# f28p65x_lin_regs register map
Vendor: Texas Instruments
Peripheral module from a debugger description file (folder C2000).
Address unit: 16 bits
Registers are 32-bit, read-write, no defined reset value unless marked. A register's access mark holds for its fields unless they carry their own. Offsets are as the file gives them; lines under a group give offsets from that group; [hi:lo] are bit positions; {n}, {i} and the like mark numbered series; 'fields as' and 'values as' point back to an identical list; <NAME> marks a mode.

## LIN_REGS — LIN Registers
0x00 SCIGCR0 — Global Control Register 0
  [0] RESET — LIN Module reset bit
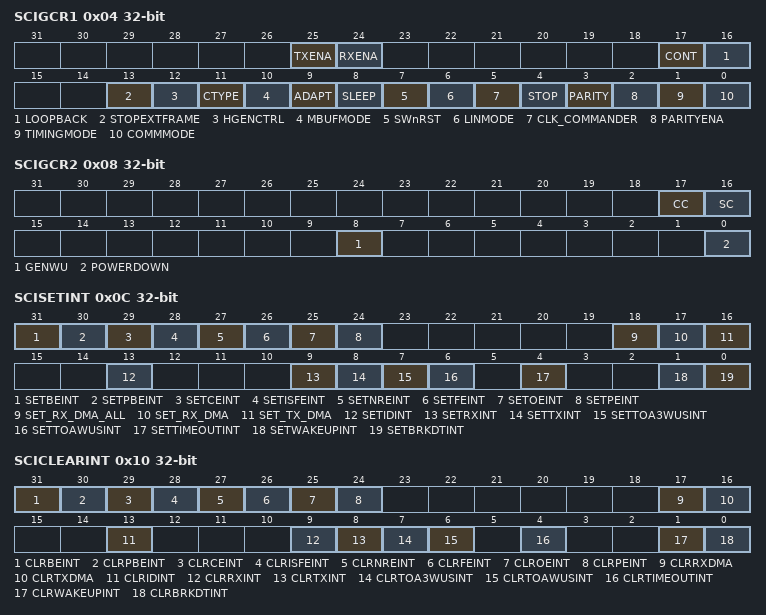
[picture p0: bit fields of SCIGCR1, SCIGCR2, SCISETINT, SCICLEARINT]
0x04 SCIGCR1 — Global Control Register 1
  [25] TXENA — Transmit enable
  [24] RXENA — Receive enable
  [17] CONT — Continue on suspend
  [16] LOOPBACK — Digital loopback mode
  [13] STOPEXTFRAME — Stop extended frame communication (LIN mode)
  [12] HGENCTRL — Mask filtering comparison control (LIN mode)
  [11] CTYPE — Checksum type (LIN mode)
  [10] MBUFMODE — Multi-buffer mode
  [9] ADAPT — Automatic baudrate adjustment control(LIN mode)
  [8] SLEEP — SCI sleep (SCI compatibility mode)
  [7] SWnRST — Software reset
  [6] LINMODE — LIN Mode enable/disable
  [5] CLK_COMMANDER — LIN Commander/Responder selection and SCI clock enable
  [4] STOP — SCI number of stop bits
  [3] PARITY — SCI parity odd/even selection
  [2] PARITYENA — Parity enable
  [1] TIMINGMODE — SCI timing mode bit. Should be set to 1 for SCI mode.
  [0] COMMMODE — SCI/LIN communications mode bit
0x08 SCIGCR2 — Global Control Register 2
  [17] CC — Compare Checksum (LIN mode)
  [16] SC — Send Checksum (LIN mode)
  [8] GENWU — Generate Wakeup
  [0] POWERDOWN — Low-power mode PowerDown bit
0x0C SCISETINT — Interrupt Enable Register
  [31] SETBEINT — Set Bit Error Interrupt (LIN only)
  [30] SETPBEINT — Set Physical Bus Error Interrupt (LIN only)
  [29] SETCEINT — Set Checksum-error Interrupt (LIN only)
  [28] SETISFEINT — Set Inconsistent-Sync-Field-Error Interrupt (LIN only)
  [27] SETNREINT — Set No-Response-Error Interrupt (LIN only)
  [26] SETFEINT — Set Framing-Error Interrupt
  [25] SETOEINT — Set Overrun-Error Interrupt
  [24] SETPEINT — Set Parity Interrupt
  [18] SET_RX_DMA_ALL — Set receiver DMA for Address and Data frames
  [17] SET_RX_DMA — Set receiver DMA
  [16] SET_TX_DMA — Set transmit DMA
  [13] SETIDINT — Set Identifier Interrupt (LIN only)
  [9] SETRXINT — Se Receiver Interrupt
  [8] SETTXINT — Set Transmitter Interrupt
  [7] SETTOA3WUSINT — Set Timeout After 3 Wakeup Signals Interrupt (LIN only)
  [6] SETTOAWUSINT — Set Timeout After Wakeup Signal Interrupt (LIN only)
  [4] SETTIMEOUTINT — Set Timeout Interrupt (LIN only)
  [1] SETWAKEUPINT — Set Wake-up Interrupt
  [0] SETBRKDTINT — Set Break-detect Interrupt (SCI compatible mode)
0x10 SCICLEARINT — Interrupt Disable Register
  [31] CLRBEINT — Clear Bit Error Interrupt (LIN only)
  [30] CLRPBEINT — Clear Physical Bus Error Interrupt (LIN only)
  [29] CLRCEINT — Clear Checksum-error Interrupt (LIN only)
  [28] CLRISFEINT — Clear Inconsistent-Sync-Field-Error Interrupt (LIN only)
  [27] CLRNREINT — Clear No-Response-Error Interrupt (LIN only)
  [26] CLRFEINT — Clear Framing-Error Interrupt
  [25] CLROEINT — Clear Overrun-Error Interrupt
  [24] CLRPEINT — Clear Parity Interrupt
  [17] CLRRXDMA — Clear receiver DMA
  [16] CLRTXDMA — Clear transmit DMA
  [13] CLRIDINT — Clear Identifier Interrupt (LIN only)
  [9] CLRRXINT — Clear Receiver Interrupt
  [8] CLRTXINT — Clear Transmitter Interrupt
  [7] CLRTOA3WUSINT — Clear Timeout After 3 Wakeup Signals Interrupt (LIN only)
  [6] CLRTOAWUSINT — Clear Timeout After Wakeup Signal Interrupt (LIN only)
  [4] CLRTIMEOUTINT — Clear Timeout Interrupt (LIN only)
  [1] CLRWAKEUPINT — Clear Wake-up Interrupt
  [0] CLRBRKDTINT — Clear Break-detect Interrupt (SCI compatible mode
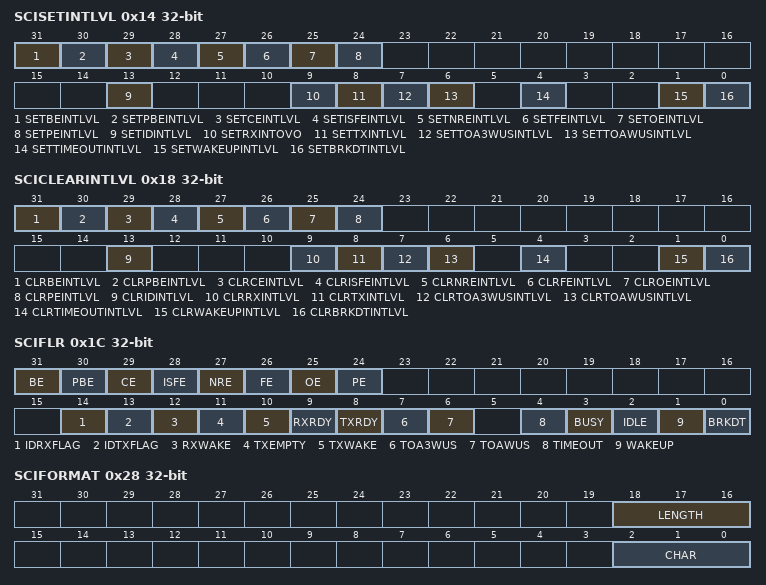
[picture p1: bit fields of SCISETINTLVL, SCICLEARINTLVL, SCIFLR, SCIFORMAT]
0x14 SCISETINTLVL — Set Interrupt Level Register
  [31] SETBEINTLVL — Set Bit Error Interrupt Level (LIN only)
  [30] SETPBEINTLVL — Set Physical Bus Error Interrupt Level (LIN only)
  [29] SETCEINTLVL — Set Checksum-error Interrupt Level (LIN only)
  [28] SETISFEINTLVL — Set Inconsistent-Sync-Field-Error Interrupt Level
  [27] SETNREINTLVL — Set No-Response-Error Interrupt Level (LIN only)
  [26] SETFEINTLVL — Set Framing-Error Interrupt Level
  [25] SETOEINTLVL — Set Overrun-Error Interrupt Level
  [24] SETPEINTLVL — Set Parity Interrupt Level
  [13] SETIDINTLVL — Set Identifier Interrupt Level (LIN only)
  [9] SETRXINTOVO — Receiver Interrupt Enable Level
  [8] SETTXINTLVL — Set Transmitter Interrupt Level
  [7] SETTOA3WUSINTLVL — Set Timeout After 3 Wakeup Signals Interrupt Level
  [6] SETTOAWUSINTLVL — Set Timeout After Wakeup Signal Interrupt Level (LIN only)
  [4] SETTIMEOUTINTLVL — Set Timeout Interrupt Level (LIN only)
  [1] SETWAKEUPINTLVL — Set Wake-up Interrupt Level
  [0] SETBRKDTINTLVL — Set Break-detect Interrupt Level (SCI compatible mode)
0x18 SCICLEARINTLVL — Clear Interrupt Level Register
  [31] CLRBEINTLVL — Clear Bit Error Interrupt Level (LIN only)
  [30] CLRPBEINTLVL — Clear Physical Bus Error Interrupt Level (LIN only)
  [29] CLRCEINTLVL — Clear Checksum-error Interrupt Level (LIN only)
  [28] CLRISFEINTLVL — Clear Inconsistent-Sync-Field-Error
  [27] CLRNREINTLVL — Clear No-Response-Error Interrupt Level (LIN only)
  [26] CLRFEINTLVL — Clear Framing-Error Interrupt Level
  [25] CLROEINTLVL — Clear Overrun-Error Interrupt Level
  [24] CLRPEINTLVL — Clear Parity Interrupt Level
  [13] CLRIDINTLVL — Clear Identifier Interrupt Level (LIN only)
  [9] CLRRXINTLVL — Clear Receiver interrupt Level.
  [8] CLRTXINTLVL — Clear Transmitter Interrupt Level
  [7] CLRTOA3WUSINTLVL — Clear Timeout After 3 Wakeup Signals
  [6] CLRTOAWUSINTLVL — Clear Timeout After Wakeup Signal Interrupt Level (LIN only)
  [4] CLRTIMEOUTINTLVL — Clear Timeout Interrupt Level (LIN only)
  [1] CLRWAKEUPINTLVL — Clear Wake-up Interrupt Level
  [0] CLRBRKDTINTLVL — Clear Break-detect Interrupt Level (SCI compatible mode)
0x1C SCIFLR access per field — Flag Register
  [31] BE rw — Bit Error Flag (LIN only)
  [30] PBE rw — Physical Bus Error Flag (LIN only)
  [29] CE rw — Checksum Error Flag (LIN only)
  [28] ISFE rw — Inconsistent Sync Field Error Flag (LIN only)
  [27] NRE rw — No-Response Error Flag (LIN only)
  [26] FE rw — Framing Error Flag
  [25] OE rw — Overrun Error Flag
  [24] PE rw — Parity Error Flag
  [14] IDRXFLAG rw — Identifier on Receive Flag
  [13] IDTXFLAG rw — Identifier On Transmit Flag (LIN only)
  [12] RXWAKE ro — Receiver Wakeup Detect Flag
  [11] TXEMPTY ro — Transmitter Empty Flag
  [10] TXWAKE rw — SCI Transmitter Wakeup Method Select
  [9] RXRDY rw — Receiver Buffer Ready Flag
  [8] TXRDY ro — Transmitter Buffer Ready Flag
  [7] TOA3WUS rw — Timeout After 3 Wakeup Signals Flag (LIN only)
  [6] TOAWUS rw — Timeout After Wakeup Signal Flag (LIN only)
  [4] TIMEOUT rw — LIN Bus IDLE timeout Flag (LIN only)
  [3] BUSY ro — Busy Flag
  [2] IDLE ro — SCI receiver in idle state (SCI compatible mode)
  [1] WAKEUP rw — Wake-up Flag
  [0] BRKDT rw — Break-detect Flag (SCI compatible mode)
0x20 SCIINTVECT0 ro — Interrupt Vector Offset Register 0
  [4:0] INTVECT0 — LIN Module reset bit
0x24 SCIINTVECT1 ro — Interrupt Vector Offset Register 1
  [4:0] INTVECT1 — LIN Module reset bit
0x28 SCIFORMAT — Length Control Register
  [18:16] LENGTH — Frame Length Control Bits
  [2:0] CHAR — Character Length Control Bits
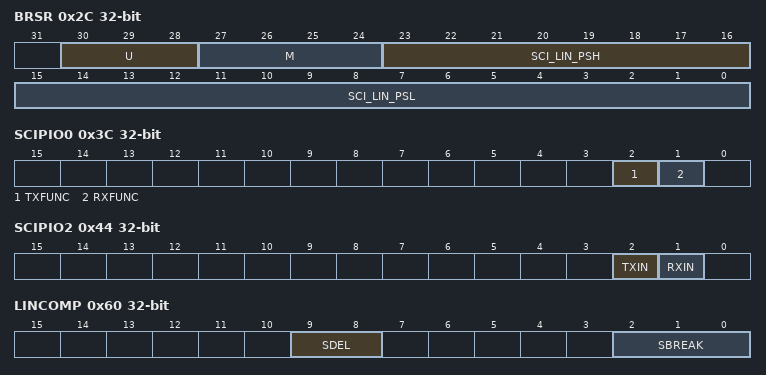
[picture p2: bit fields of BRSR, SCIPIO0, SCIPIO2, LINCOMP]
0x2C BRSR — Baud Rate Selection Register
  [30:28] U — U Superfractional divider Selection
  [27:24] M — M 4-bit Fractional Divider selection
  [23:16] SCI_LIN_PSH — 24-Bit Integer Prescaler Select (High Bits)
  [15:0] SCI_LIN_PSL — 24-Bit Integer Prescaler Select (Low Bits)
0x30 SCIED ro — Emulation buffer Register
  [7:0] ED — Receiver Emulation Data.
0x34 SCIRD ro — Receiver data buffer Register
  [7:0] RD — Received Data.
0x38 SCITD — Transmit data buffer Register
  [7:0] TD — Transmit data
0x3C SCIPIO0 — Pin control Register 0
  [2] TXFUNC — LINTX pin function
  [1] RXFUNC — LINRX pin function
0x44 SCIPIO2 ro — Pin control Register 2
  [2] TXIN — SCITX pin value
  [1] RXIN — SCIRX pin value
0x60 LINCOMP — Compare register
  [9:8] SDEL — Sync Delimiter Compare
  [2:0] SBREAK — Sync Break Extend
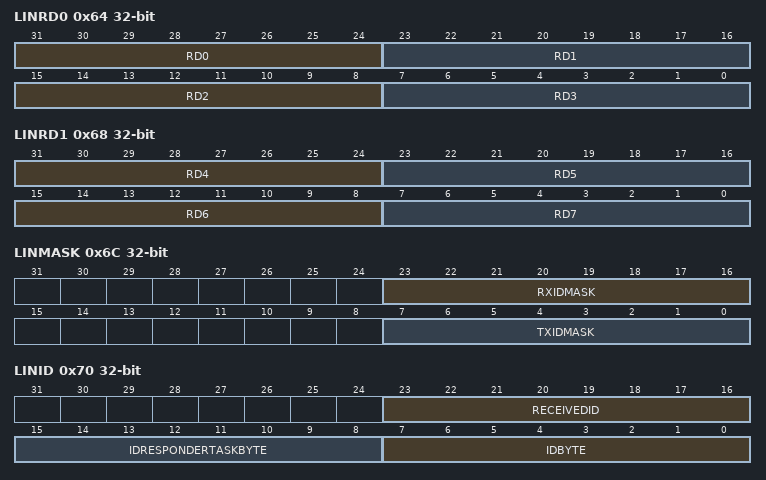
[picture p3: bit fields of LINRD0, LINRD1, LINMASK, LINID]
0x64 LINRD0 ro — Receive data register 0
  [31-8n:24-8n] RD{n} (n=0..3) — Receive Buffer {n}
0x68 LINRD1 ro — Receive data register 1
  [63-8n:56-8n] RD{n} (n=4..7) — Receive Buffer {n-4}
0x6C LINMASK — Acceptance mask register
  [23:16] RXIDMASK — RX ID Mask bits (LIN only)
  [7:0] TXIDMASK — TX ID Mask bits (LIN only)
0x70 LINID access per field
  [23:16] RECEIVEDID ro — Current Message ID (LIN only)
  [15:8] IDRESPONDERTASKBYTE rw — ID Responder Task byte (LIN only)
  [7:0] IDBYTE rw — LIN message ID (LIN only)
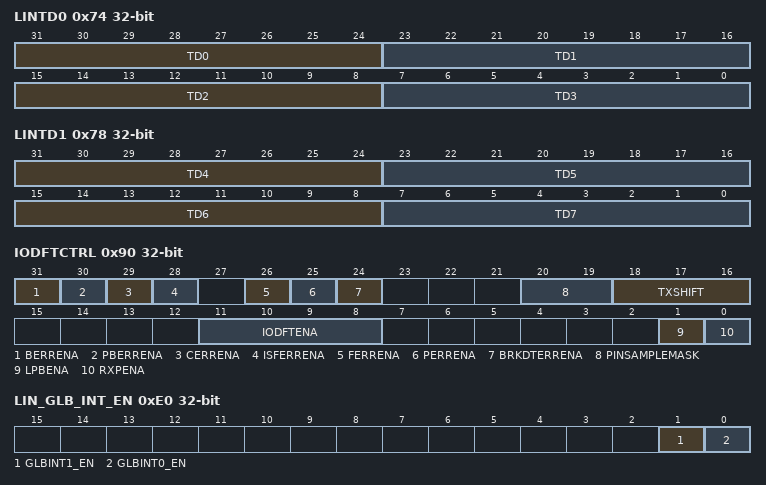
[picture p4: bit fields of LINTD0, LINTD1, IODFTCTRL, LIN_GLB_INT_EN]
0x74 LINTD0 — Transmit Data Register 0
  [31-8n:24-8n] TD{n} (n=0..3) — TRANSMIT Buffer {n}
0x78 LINTD1 — Transmit Data Register 1
  [63-8n:56-8n] TD{n} (n=4..7) — TRANSMIT Buffer {n}
0x7C MBRSR — Maximum Baud Rate Selection Register
  [12:0] MBR — Received Data.
0x90 IODFTCTRL — IODFT for LIN
  [31] BERRENA — Bit Error Enable (LIN mode)
  [30] PBERRENA — Physical Bus Error Enable (LIN mode)
  [29] CERRENA — Checksum Error Enable(LIN mode)
  [28] ISFERRENA — Inconsistent Sync Field Error Enable (LIN mode)
  [26] FERRENA — Frame Error Enable (SCI compatibility mode)
  [25] PERRENA — Parity Error Enable (SCI compatibility mode)
  [24] BRKDTERRENA — Break Detect Error Enable (SCI compatibility mode)
  [20:19] PINSAMPLEMASK — TX Pin Sample Mask
  [18:16] TXSHIFT — Transmit Delay Shift
  [11:8] IODFTENA — IO DFT Enable Key
  [1] LPBENA — Module Loopback Enable
  [0] RXPENA — Analog Loopback Via Receive Pin Enable
0xE0 LIN_GLB_INT_EN — LIN Global Interrupt Enable Register
  [1] GLBINT1_EN — Global Interrupt Enable for LIN INT1
  [0] GLBINT0_EN — Global Interrupt Enable for LIN INT0
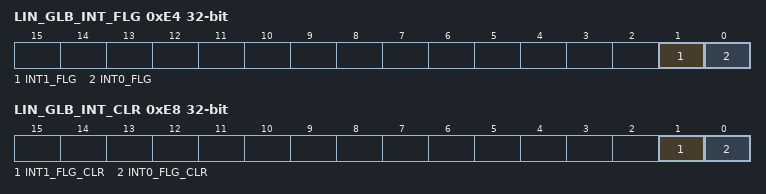
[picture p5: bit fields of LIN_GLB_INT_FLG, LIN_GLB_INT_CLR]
0xE4 LIN_GLB_INT_FLG ro — LIN Global Interrupt Flag Register
  [1] INT1_FLG — Global Interrupt Flag for LIN INT1
  [0] INT0_FLG — Global Interrupt Flag for LIN INT0
0xE8 LIN_GLB_INT_CLR — LIN Global Interrupt Clear Register
  [1] INT1_FLG_CLR — Global Interrupt flag clear for LIN INT1
  [0] INT0_FLG_CLR — Global Interrupt flag clear for LIN INT0
